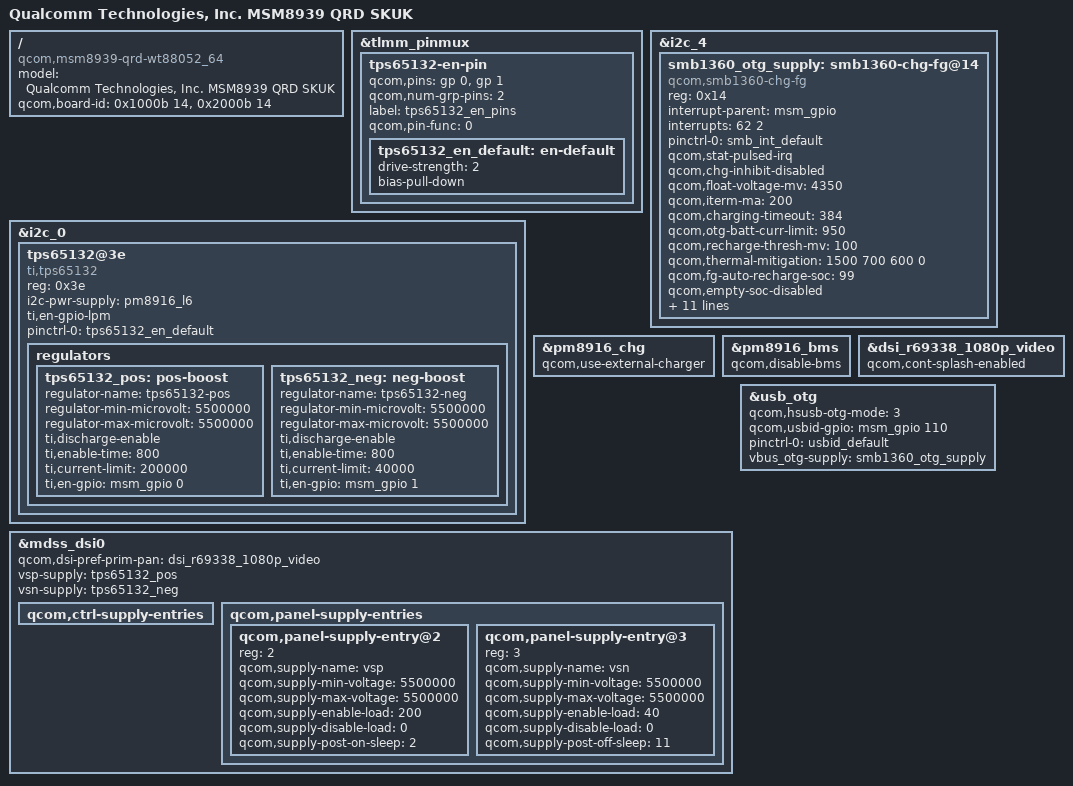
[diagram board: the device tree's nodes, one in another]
/* Copyright (c) 2014, The Linux Foundation. All rights reserved.
 *
 * This program is free software; you can redistribute it and/or modify
 * it under the terms of the GNU General Public License version 2 and
 * only version 2 as published by the Free Software Foundation.
 *
 * This program is distributed in the hope that it will be useful,
 * but WITHOUT ANY WARRANTY; without even the implied warranty of
 * MERCHANTABILITY or FITNESS FOR A PARTICULAR PURPOSE.  See the
 * GNU General Public License for more details.
 */

/dts-v1/;

#include "msm8939.dtsi"
#include "msm8939-qrd-wt88052_64.dtsi"
#include "dsi-panel-r69338-tdi-1080p-video.dtsi"

/ {
	model = "Qualcomm Technologies, Inc. MSM8939 QRD SKUK";
	compatible = "qcom,msm8939-qrd-wt88052_64", "qcom,msm8939-qrd", "qcom,msm8939", "qcom,qrd";
	qcom,board-id = <0x1000b 14>, <0x2000b 14>;
};

&tlmm_pinmux {
	tps65132-en-pin {
		qcom,pins = <&gp 0>, <&gp 1>;
		qcom,num-grp-pins = <2>;
		label = "tps65132_en_pins";
		qcom,pin-func = <0>;

		tps65132_en_default: en-default {
			drive-strength = <2>;
			bias-pull-down;
		};
	};
};

&i2c_0 { /* BLSP1 QUP2 */
	tps65132@3e {
		compatible = "ti,tps65132";
		reg = <0x3e>;
		i2c-pwr-supply = <&pm8916_l6>;
		ti,en-gpio-lpm;
		pinctrl-names = "default";
		pinctrl-0 = <&tps65132_en_default>;

		regulators {
			tps65132_pos: pos-boost {
				regulator-name = "tps65132-pos";
				regulator-min-microvolt = <5500000>;
				regulator-max-microvolt = <5500000>;
				ti,discharge-enable;
				ti,enable-time = <800>;
				ti,current-limit = <200000>;
				ti,en-gpio = <&msm_gpio 0 0>;
			};

			tps65132_neg: neg-boost {
				regulator-name = "tps65132-neg";
				regulator-min-microvolt = <5500000>;
				regulator-max-microvolt = <5500000>;
				ti,discharge-enable;
				ti,enable-time = <800>;
				ti,current-limit = <40000>;
				ti,en-gpio = <&msm_gpio 1 0>;
			};
		};
	};
};

&i2c_4 {
	smb1360_otg_supply: smb1360-chg-fg@14 {
		compatible = "qcom,smb1360-chg-fg";
		reg = <0x14>;
		interrupt-parent = <&msm_gpio>;
		interrupts = <62 2>;
		pinctrl-names = "default";
		pinctrl-0 = <&smb_int_default>;
		qcom,stat-pulsed-irq;
		qcom,chg-inhibit-disabled;
		qcom,float-voltage-mv = <4350>;
		qcom,iterm-ma = <200>;
		qcom,charging-timeout = <384>;
		qcom,otg-batt-curr-limit = <950>;
		qcom,recharge-thresh-mv = <100>;
		qcom,thermal-mitigation = <1500 700 600 0>;
		qcom,fg-auto-recharge-soc = <99>;
		qcom,empty-soc-disabled;
		regulator-name = "smb1360_otg_vreg";
		qcom,awake-min-soc;
		qcom,batt-profile-select;
		qcom,smb1360-vadc = <&pm8916_vadc>;
		qcom,batt-id-vref-uv = <1800000>;
		qcom,batt-id-rpullup-kohm = <100>;
		qcom,profile-a-rid-kohm = <33>;
		qcom,profile-b-rid-kohm = <91>;
		qcom,config-hard-thresholds;
		qcom,hot-bat-decidegc = <550>;
		qcom,cold-bat-decidegc = <(-150)>;
	};
};

&pm8916_chg {
	status = "ok";
	qcom,use-external-charger;
};

&pm8916_bms {
	status = "ok";
	qcom,disable-bms;
};

&mdss_dsi0 {
	qcom,dsi-pref-prim-pan = <&dsi_r69338_1080p_video>;

	vsp-supply = <&tps65132_pos>;
	vsn-supply = <&tps65132_neg>;

	qcom,ctrl-supply-entries {
		/delete-node/ qcom,ctrl-supply-entry@0;
	};

	qcom,panel-supply-entries {
		#address-cells = <1>;
		#size-cells = <0>;
		
		qcom,panel-supply-entry@2 {
			reg = <2>;
			qcom,supply-name = "vsp";
			qcom,supply-min-voltage = <5500000>;
			qcom,supply-max-voltage = <5500000>;
			qcom,supply-enable-load = <200>;
			qcom,supply-disable-load = <0>;
			qcom,supply-post-on-sleep = <2>;

		};

		qcom,panel-supply-entry@3 {
			reg = <3>;
			qcom,supply-name = "vsn";
			qcom,supply-min-voltage = <5500000>;
			qcom,supply-max-voltage = <5500000>;
			qcom,supply-enable-load = <40>;
			qcom,supply-disable-load = <0>;
			qcom,supply-post-off-sleep = <11>;
		};
	};
};

&dsi_r69338_1080p_video {
	qcom,cont-splash-enabled;
};

&usb_otg {
       qcom,hsusb-otg-mode = <3>;
       qcom,usbid-gpio = <&msm_gpio 110 0>;
       pinctrl-names = "default";
       pinctrl-0 = <&usbid_default>;
       vbus_otg-supply = <&smb1360_otg_supply>;
};

